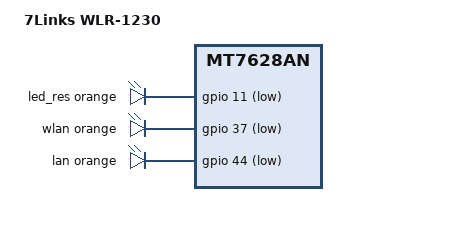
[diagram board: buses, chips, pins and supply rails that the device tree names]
// SPDX-License-Identifier: GPL-2.0-or-later OR MIT

#include "mt7628an_7links_wlr-12xx.dtsi"

/ {
	compatible = "7links,wlr-1230", "mediatek,mt7628an-soc";
	model = "7Links WLR-1230";

	leds {
		compatible = "gpio-leds";

		led_res: res {
			function = LED_FUNCTION_STATUS;
			color = <LED_COLOR_ID_ORANGE>;
			gpios = <&gpio 11 GPIO_ACTIVE_LOW>;
			default-state = "on";
		};

		wlan {
			function = LED_FUNCTION_WLAN;
			color = <LED_COLOR_ID_ORANGE>;
			gpios = <&gpio 37 GPIO_ACTIVE_LOW>;
			linux,default-trigger = "phy1tpt";
		};

		lan {
			function = LED_FUNCTION_LAN;
			color = <LED_COLOR_ID_ORANGE>;
			gpios = <&gpio 44 GPIO_ACTIVE_LOW>;
		};
	};

	aliases {
		led-boot = &led_res;
		led-failsafe = &led_res;
		led-running = &led_res;
		led-upgrade = &led_res;
		label-mac-device = &ethernet;
	};
};
